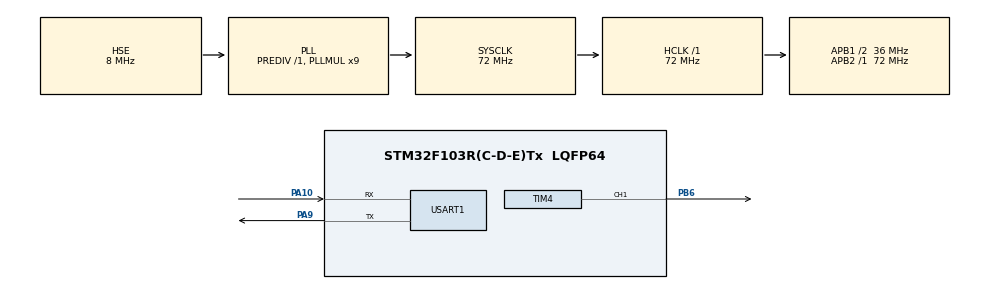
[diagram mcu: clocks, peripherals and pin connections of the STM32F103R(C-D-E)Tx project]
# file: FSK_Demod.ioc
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Mcu.Family=STM32F1
Mcu.Name=STM32F103R(C-D-E)Tx
Mcu.Package=LQFP64
NVIC.PriorityGroup=NVIC_PRIORITYGROUP_4
PA10.Mode=Asynchronous
PA10.Signal=USART1_RX
PA13.Mode=Serial_Wire
PA13.Signal=SYS_JTMS-SWDIO
PA14.Mode=Serial_Wire
PA14.Signal=SYS_JTCK-SWCLK
PA9.Mode=Asynchronous
PA9.Signal=USART1_TX
PB6.Signal=S_TIM4_CH1
PC14-OSC32_IN.Mode=LSE-External-Oscillator
PC14-OSC32_IN.Signal=RCC_OSC32_IN
PC15-OSC32_OUT.Mode=LSE-External-Oscillator
PC15-OSC32_OUT.Signal=RCC_OSC32_OUT
PD0-OSC_IN.Mode=HSE-External-Oscillator
PD0-OSC_IN.Signal=RCC_OSC_IN
PD1-OSC_OUT.Mode=HSE-External-Oscillator
PD1-OSC_OUT.Signal=RCC_OSC_OUT
ProjectManager.HeapSize=0x200
ProjectManager.StackSize=0x400
ProjectManager.TargetToolchain=STM32CubeIDE
RCC.AHBFreq_Value=72000000
RCC.APB1CLKDivider=RCC_HCLK_DIV2
RCC.APB1Freq_Value=36000000
RCC.APB1TimFreq_Value=72000000
RCC.APB2Freq_Value=72000000
RCC.APB2TimFreq_Value=72000000
RCC.HCLKFreq_Value=72000000
RCC.PLLMUL=RCC_PLL_MUL9
RCC.PLLSourceVirtual=RCC_PLLSOURCE_HSE
RCC.SYSCLKFreq_VALUE=72000000
RCC.SYSCLKSource=RCC_SYSCLKSOURCE_PLLCLK
RCC.USBFreq_Value=72000000
SH.S_TIM4_CH1.0=TIM4_CH1,PWM Generation1 CH1
TIM4.Channel-PWM\ Generation1\ CH1=TIM_CHANNEL_1
TIM4.Period=9
TIM4.Prescaler=999
TIM4.Pulse-PWM\ Generation1\ CH1=4
USART1.VirtualMode=VM_ASYNC
VP_TIM4_VS_ClockSourceINT.Mode=Internal
board=custom

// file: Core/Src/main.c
/* USER CODE BEGIN Header */
/**
 ******************************************************************************
 * @file           : main.c
 * @brief          : Main program body
 ******************************************************************************
 * @attention
 *
 * <h2><center>&copy; Copyright (c) 2020 STMicroelectronics.
 * All rights reserved.</center></h2>
 *
 * This software component is licensed by ST under BSD 3-Clause license,
 * the "License"; You may not use this file except in compliance with the
 * License. You may obtain a copy of the License at:
 *                        opensource.org/licenses/BSD-3-Clause
 *
 ******************************************************************************
 */
/* USER CODE END Header */
#include "main.h"

/* USER CODE BEGIN Includes */
#include <string.h>
/* USER CODE END Includes */

TIM_HandleTypeDef htim4;

UART_HandleTypeDef huart1;

void SystemClock_Config(void);
static void MX_GPIO_Init(void);
static void MX_TIM4_Init(void);
static void MX_USART1_UART_Init(void);

int main(void)
{

  /* MCU Configuration--------------------------------------------------------*/

  /* Reset of all peripherals, Initializes the Flash interface and the Systick. */
  HAL_Init();

  /* Configure the system clock */
  SystemClock_Config();

  /* Initialize all configured peripherals */
  MX_GPIO_Init();
  MX_TIM4_Init();
  MX_USART1_UART_Init();
  /* USER CODE BEGIN 2 */

  afsk_init(&htim4, 2);

  //  HAL_Delay(100);
  uint8_t msg[]="Init...\r\nStarting Telemetry test.\r\n"
      "Device ID   : 0x414\r\n"
      "Revision ID : Rev X\r\n"
      "Device name : STM32F101/F103 High-density\r\n"
      "Flash size  : 256 KBytes\r\n"
      "Device type : MCU\r\n"
      "Device CPU  : Cortex-M3\r\n";

  /* USER CODE END 2 */

  /* Infinite loop */
  /* USER CODE BEGIN WHILE */
  while (1)
    {

      send_msg(msg,strlen((char*)msg));

      while(1);

      /* USER CODE END WHILE */

    }
}

void SystemClock_Config(void)
{
  RCC_OscInitTypeDef RCC_OscInitStruct = {0};
  RCC_ClkInitTypeDef RCC_ClkInitStruct = {0};

  /** Initializes the RCC Oscillators according to the specified parameters
   * in the RCC_OscInitTypeDef structure.
   */
  RCC_OscInitStruct.OscillatorType = RCC_OSCILLATORTYPE_HSE;
  RCC_OscInitStruct.HSEState = RCC_HSE_ON;
  RCC_OscInitStruct.HSEPredivValue = RCC_HSE_PREDIV_DIV1;
  RCC_OscInitStruct.HSIState = RCC_HSI_ON;
  RCC_OscInitStruct.PLL.PLLState = RCC_PLL_ON;
  RCC_OscInitStruct.PLL.PLLSource = RCC_PLLSOURCE_HSE;
  RCC_OscInitStruct.PLL.PLLMUL = RCC_PLL_MUL9;
  if (HAL_RCC_OscConfig(&RCC_OscInitStruct) != HAL_OK)
    {
      Error_Handler();
    }
  /** Initializes the CPU, AHB and APB buses clocks
   */
  RCC_ClkInitStruct.ClockType = RCC_CLOCKTYPE_HCLK|RCC_CLOCKTYPE_SYSCLK
      |RCC_CLOCKTYPE_PCLK1|RCC_CLOCKTYPE_PCLK2;
  RCC_ClkInitStruct.SYSCLKSource = RCC_SYSCLKSOURCE_PLLCLK;
  RCC_ClkInitStruct.AHBCLKDivider = RCC_SYSCLK_DIV1;
  RCC_ClkInitStruct.APB1CLKDivider = RCC_HCLK_DIV2;
  RCC_ClkInitStruct.APB2CLKDivider = RCC_HCLK_DIV1;

  if (HAL_RCC_ClockConfig(&RCC_ClkInitStruct, FLASH_LATENCY_2) != HAL_OK)
    {
      Error_Handler();
    }
}

static void MX_TIM4_Init(void)
{

  TIM_ClockConfigTypeDef sClockSourceConfig = {0};
  TIM_MasterConfigTypeDef sMasterConfig = {0};
  TIM_OC_InitTypeDef sConfigOC = {0};

  htim4.Instance = TIM4;
  htim4.Init.Prescaler = 999;
  htim4.Init.CounterMode = TIM_COUNTERMODE_UP;
  htim4.Init.Period = 19;
  htim4.Init.ClockDivision = TIM_CLOCKDIVISION_DIV1;
  htim4.Init.AutoReloadPreload = TIM_AUTORELOAD_PRELOAD_DISABLE;
  if (HAL_TIM_Base_Init(&htim4) != HAL_OK)
    {
      Error_Handler();
    }
  sClockSourceConfig.ClockSource = TIM_CLOCKSOURCE_INTERNAL;
  if (HAL_TIM_ConfigClockSource(&htim4, &sClockSourceConfig) != HAL_OK)
    {
      Error_Handler();
    }
  if (HAL_TIM_PWM_Init(&htim4) != HAL_OK)
    {
      Error_Handler();
    }
  sMasterConfig.MasterOutputTrigger = TIM_TRGO_RESET;
  sMasterConfig.MasterSlaveMode = TIM_MASTERSLAVEMODE_DISABLE;
  if (HAL_TIMEx_MasterConfigSynchronization(&htim4, &sMasterConfig) != HAL_OK)
    {
      Error_Handler();
    }
  sConfigOC.OCMode = TIM_OCMODE_PWM1;
  sConfigOC.Pulse = 9;
  sConfigOC.OCPolarity = TIM_OCPOLARITY_HIGH;
  sConfigOC.OCFastMode = TIM_OCFAST_DISABLE;
  if (HAL_TIM_PWM_ConfigChannel(&htim4, &sConfigOC, TIM_CHANNEL_1) != HAL_OK)
    {
      Error_Handler();
    }
  HAL_TIM_MspPostInit(&htim4);

}

static void MX_USART1_UART_Init(void)
{

  huart1.Instance = USART1;
  huart1.Init.BaudRate = 115200;
  huart1.Init.WordLength = UART_WORDLENGTH_8B;
  huart1.Init.StopBits = UART_STOPBITS_1;
  huart1.Init.Parity = UART_PARITY_NONE;
  huart1.Init.Mode = UART_MODE_TX_RX;
  huart1.Init.HwFlowCtl = UART_HWCONTROL_NONE;
  huart1.Init.OverSampling = UART_OVERSAMPLING_16;
  if (HAL_UART_Init(&huart1) != HAL_OK)
    {
      Error_Handler();
    }

}

static void MX_GPIO_Init(void)
{

  /* GPIO Ports Clock Enable */
  __HAL_RCC_GPIOC_CLK_ENABLE();
  __HAL_RCC_GPIOD_CLK_ENABLE();
  __HAL_RCC_GPIOA_CLK_ENABLE();
  __HAL_RCC_GPIOB_CLK_ENABLE();

}

void Error_Handler(void)
{
}

/************************ (C) COPYRIGHT STMicroelectronics *****END OF FILE****/
